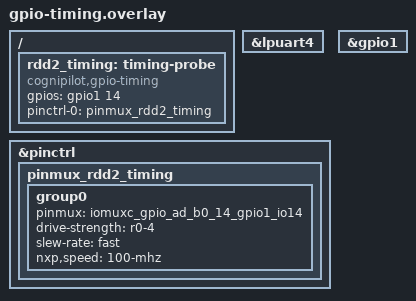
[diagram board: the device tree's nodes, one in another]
/* SPDX-License-Identifier: Apache-2.0 */
#include <zephyr/dt-bindings/gpio/gpio.h>

/ {
  rdd2_timing: timing-probe {
    compatible = "cognipilot,gpio-timing";
    /* J7 AUX pin 5: GPIO_AD_B0_14 / GPIO1_IO14 (AUX_RTS). */
    gpios = <&gpio1 14 GPIO_ACTIVE_HIGH>;
    pinctrl-0 = <&pinmux_rdd2_timing>;
    pinctrl-names = "default";
  };
};

/* Keep J7 UART TX/RX available, but reserve RTS for the timing probe.
 * The probe applies its GPIO pad mux during main initialization, after UART
 * device initialization. Do not enable runtime UART flow control in this build.
 */
&lpuart4 {
  /delete-property/ hw-flow-control;
};

&pinctrl {
  pinmux_rdd2_timing: pinmux_rdd2_timing {
    group0 {
      pinmux = <&iomuxc_gpio_ad_b0_14_gpio1_io14>;
      drive-strength = "r0-4";
      slew-rate = "fast";
      nxp,speed = "100-mhz";
    };
  };
};

&gpio1 {
  status = "okay";
};
